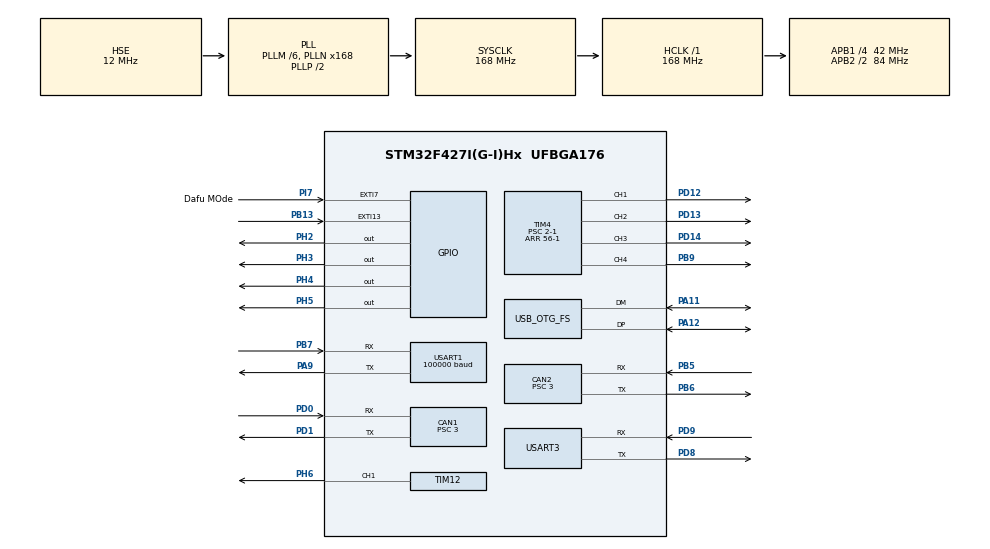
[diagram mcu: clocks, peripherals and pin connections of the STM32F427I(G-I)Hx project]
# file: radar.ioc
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CAN1.ABOM=ENABLE
CAN1.AWUM=DISABLE
CAN1.BS1=CAN_BS1_10TQ
CAN1.BS2=CAN_BS2_3TQ
CAN1.CalculateBaudRate=1000000
CAN1.CalculateTimeBit=1000
CAN1.CalculateTimeQuantum=71.42857142857143
CAN1.Prescaler=3
CAN1.TXFP=DISABLE
CAN2.ABOM=ENABLE
CAN2.AWUM=DISABLE
CAN2.BS1=CAN_BS1_10TQ
CAN2.BS2=CAN_BS2_3TQ
CAN2.CalculateBaudRate=1000000
CAN2.CalculateTimeBit=1000
CAN2.CalculateTimeQuantum=71.42857142857143
CAN2.Prescaler=3
CAN2.TXFP=DISABLE
Dma.Request0=TIM4_CH1
Dma.Request1=TIM4_CH3
Dma.Request2=TIM4_UP
Dma.Request3=USART1_RX
Dma.Request4=USART3_RX
Dma.Request5=USART3_TX
Dma.TIM4_CH1.0.Direction=DMA_MEMORY_TO_PERIPH
Dma.TIM4_CH1.0.FIFOMode=DMA_FIFOMODE_DISABLE
Dma.TIM4_CH1.0.Instance=DMA1_Stream0
Dma.TIM4_CH1.0.MemDataAlignment=DMA_MDATAALIGN_WORD
Dma.TIM4_CH1.0.MemInc=DMA_MINC_ENABLE
Dma.TIM4_CH1.0.Mode=DMA_CIRCULAR
Dma.TIM4_CH1.0.PeriphDataAlignment=DMA_PDATAALIGN_WORD
Dma.TIM4_CH1.0.PeriphInc=DMA_PINC_DISABLE
Dma.TIM4_CH1.0.Priority=DMA_PRIORITY_MEDIUM
Dma.TIM4_CH3.1.Direction=DMA_MEMORY_TO_PERIPH
Dma.TIM4_CH3.1.FIFOMode=DMA_FIFOMODE_DISABLE
Dma.TIM4_CH3.1.Instance=DMA1_Stream7
Dma.TIM4_CH3.1.MemDataAlignment=DMA_MDATAALIGN_HALFWORD
Dma.TIM4_CH3.1.MemInc=DMA_MINC_ENABLE
Dma.TIM4_CH3.1.Mode=DMA_CIRCULAR
Dma.TIM4_CH3.1.PeriphDataAlignment=DMA_PDATAALIGN_HALFWORD
Dma.TIM4_CH3.1.PeriphInc=DMA_PINC_DISABLE
Dma.TIM4_CH3.1.Priority=DMA_PRIORITY_MEDIUM
Dma.TIM4_UP.2.Direction=DMA_MEMORY_TO_PERIPH
Dma.TIM4_UP.2.FIFOMode=DMA_FIFOMODE_DISABLE
Dma.TIM4_UP.2.Instance=DMA1_Stream6
Dma.TIM4_UP.2.MemDataAlignment=DMA_MDATAALIGN_HALFWORD
Dma.TIM4_UP.2.MemInc=DMA_MINC_ENABLE
Dma.TIM4_UP.2.Mode=DMA_CIRCULAR
Dma.TIM4_UP.2.PeriphDataAlignment=DMA_PDATAALIGN_HALFWORD
Dma.TIM4_UP.2.PeriphInc=DMA_PINC_DISABLE
Dma.TIM4_UP.2.Priority=DMA_PRIORITY_MEDIUM
Dma.USART1_RX.3.Direction=DMA_PERIPH_TO_MEMORY
Dma.USART1_RX.3.FIFOMode=DMA_FIFOMODE_DISABLE
Dma.USART1_RX.3.Instance=DMA2_Stream2
Dma.USART1_RX.3.MemDataAlignment=DMA_MDATAALIGN_BYTE
Dma.USART1_RX.3.MemInc=DMA_MINC_ENABLE
Dma.USART1_RX.3.Mode=DMA_NORMAL
Dma.USART1_RX.3.PeriphDataAlignment=DMA_PDATAALIGN_BYTE
Dma.USART1_RX.3.PeriphInc=DMA_PINC_DISABLE
Dma.USART1_RX.3.Priority=DMA_PRIORITY_VERY_HIGH
Dma.USART3_RX.4.Direction=DMA_PERIPH_TO_MEMORY
Dma.USART3_RX.4.FIFOMode=DMA_FIFOMODE_DISABLE
Dma.USART3_RX.4.Instance=DMA1_Stream1
Dma.USART3_RX.4.MemDataAlignment=DMA_MDATAALIGN_BYTE
Dma.USART3_RX.4.MemInc=DMA_MINC_ENABLE
Dma.USART3_RX.4.Mode=DMA_NORMAL
Dma.USART3_RX.4.PeriphDataAlignment=DMA_PDATAALIGN_BYTE
Dma.USART3_RX.4.PeriphInc=DMA_PINC_DISABLE
Dma.USART3_RX.4.Priority=DMA_PRIORITY_LOW
Dma.USART3_TX.5.Direction=DMA_MEMORY_TO_PERIPH
Dma.USART3_TX.5.FIFOMode=DMA_FIFOMODE_DISABLE
Dma.USART3_TX.5.Instance=DMA1_Stream3
Dma.USART3_TX.5.MemDataAlignment=DMA_MDATAALIGN_BYTE
Dma.USART3_TX.5.MemInc=DMA_MINC_ENABLE
Dma.USART3_TX.5.Mode=DMA_NORMAL
Dma.USART3_TX.5.PeriphDataAlignment=DMA_PDATAALIGN_BYTE
Dma.USART3_TX.5.PeriphInc=DMA_PINC_DISABLE
Dma.USART3_TX.5.Priority=DMA_PRIORITY_LOW
Mcu.Family=STM32F4
Mcu.Name=STM32F427I(G-I)Hx
Mcu.Package=UFBGA176
NVIC.CAN1_RX0_IRQn=true\:0\:0\:false\:false\:true\:true\:true\:true
NVIC.CAN2_RX0_IRQn=true\:1\:0\:true\:false\:true\:true\:true\:true
NVIC.DMA1_Stream0_IRQn=true\:0\:0\:false\:false\:true\:false\:true\:true
NVIC.DMA1_Stream1_IRQn=true\:0\:0\:false\:false\:true\:false\:true\:true
NVIC.DMA1_Stream3_IRQn=true\:0\:0\:false\:false\:true\:false\:true\:true
NVIC.DMA1_Stream6_IRQn=true\:0\:0\:false\:false\:true\:false\:true\:true
NVIC.DMA1_Stream7_IRQn=true\:1\:0\:true\:false\:true\:false\:true\:true
NVIC.DMA2_Stream2_IRQn=true\:1\:0\:true\:false\:true\:false\:true\:true
NVIC.EXTI9_5_IRQn=true\:1\:0\:true\:false\:true\:true\:true\:true
NVIC.OTG_FS_IRQn=true\:0\:0\:false\:false\:true\:true\:true\:true
NVIC.PriorityGroup=NVIC_PRIORITYGROUP_4
NVIC.TIM8_TRG_COM_TIM14_IRQn=true\:1\:0\:true\:false\:true\:true\:true\:true
NVIC.USART1_IRQn=true\:5\:0\:true\:false\:true\:true\:true\:true
NVIC.USART3_IRQn=true\:0\:0\:false\:false\:true\:true\:true\:true
PA11.Mode=Device_Only
PA11.Signal=USB_OTG_FS_DM
PA12.Mode=Device_Only
PA12.Signal=USB_OTG_FS_DP
PA13.Mode=Serial_Wire
PA13.Signal=SYS_JTMS-SWDIO
PA14.Mode=Serial_Wire
PA14.Signal=SYS_JTCK-SWCLK
PA9.Mode=Asynchronous
PA9.Signal=USART1_TX
PB13.Signal=GPXTI13
PB5.Mode=CAN_Activate
PB5.Signal=CAN2_RX
PB6.Mode=CAN_Activate
PB6.Signal=CAN2_TX
PB7.Mode=Asynchronous
PB7.Signal=USART1_RX
PB9.Signal=S_TIM4_CH4
PC14/OSC32_IN.Mode=LSE-External-Oscillator
PC14/OSC32_IN.Signal=RCC_OSC32_IN
PC15/OSC32_OUT.Mode=LSE-External-Oscillator
PC15/OSC32_OUT.Signal=RCC_OSC32_OUT
PD0.Mode=CAN_Activate
PD0.Signal=CAN1_RX
PD1.Mode=CAN_Activate
PD1.Signal=CAN1_TX
PD12.Signal=S_TIM4_CH1
PD13.Signal=S_TIM4_CH2
PD14.Signal=S_TIM4_CH3
PD8.Mode=Asynchronous
PD8.Signal=USART3_TX
PD9.Mode=Asynchronous
PD9.Signal=USART3_RX
PH0/OSC_IN.Mode=HSE-External-Oscillator
PH0/OSC_IN.Signal=RCC_OSC_IN
PH1/OSC_OUT.Mode=HSE-External-Oscillator
PH1/OSC_OUT.Signal=RCC_OSC_OUT
PH2.GPIO_Speed=GPIO_SPEED_FREQ_VERY_HIGH
PH2.PinState=GPIO_PIN_SET
PH2.Signal=GPIO_Output
PH3.GPIO_Speed=GPIO_SPEED_FREQ_VERY_HIGH
PH3.PinState=GPIO_PIN_SET
PH3.Signal=GPIO_Output
PH4.GPIO_Speed=GPIO_SPEED_FREQ_VERY_HIGH
PH4.PinState=GPIO_PIN_SET
PH4.Signal=GPIO_Output
PH5.GPIO_Speed=GPIO_SPEED_FREQ_VERY_HIGH
PH5.PinState=GPIO_PIN_SET
PH5.Signal=GPIO_Output
PH6.Signal=S_TIM12_CH1
PI7.GPIO_Label=Dafu MOde
PI7.GPIO_ModeDefaultEXTI=GPIO_MODE_IT_FALLING
PI7.GPIO_PuPd=GPIO_PULLUP
PI7.Signal=GPXTI7
ProjectManager.HeapSize=0x200
ProjectManager.StackSize=0x400
ProjectManager.TargetToolchain=CMake
RCC.48MHZClocksFreq_Value=48000000
RCC.AHBFreq_Value=168000000
RCC.APB1CLKDivider=RCC_HCLK_DIV4
RCC.APB1Freq_Value=42000000
RCC.APB1TimFreq_Value=84000000
RCC.APB2CLKDivider=RCC_HCLK_DIV2
RCC.APB2Freq_Value=84000000
RCC.APB2TimFreq_Value=168000000
RCC.CortexFreq_Value=168000000
RCC.HCLKFreq_Value=168000000
RCC.HSE_VALUE=12000000
RCC.HSI_VALUE=16000000
RCC.PLLM=6
RCC.PLLN=168
RCC.PLLQ=7
RCC.SYSCLKFreq_VALUE=168000000
RCC.SYSCLKSource=RCC_SYSCLKSOURCE_PLLCLK
RCC.VCOOutputFreq_Value=336000000
SH.S_TIM12_CH1.0=TIM12_CH1,PWM Generation1 CH1
SH.S_TIM4_CH1.0=TIM4_CH1,PWM Generation1 CH1
SH.S_TIM4_CH2.0=TIM4_CH2,PWM Generation2 CH2
SH.S_TIM4_CH3.0=TIM4_CH3,PWM Generation3 CH3
SH.S_TIM4_CH4.0=TIM4_CH4,PWM Generation4 CH4
TIM12.AutoReloadPreload=TIM_AUTORELOAD_PRELOAD_ENABLE
TIM12.Channel-PWM\ Generation1\ CH1=TIM_CHANNEL_1
TIM12.Period=1
TIM12.Prescaler=1
TIM14.Period=2000-1
TIM14.Prescaler=90-1
TIM4.Channel-PWM\ Generation1\ CH1=TIM_CHANNEL_1
TIM4.Channel-PWM\ Generation2\ CH2=TIM_CHANNEL_2
TIM4.Channel-PWM\ Generation3\ CH3=TIM_CHANNEL_3
TIM4.Channel-PWM\ Generation4\ CH4=TIM_CHANNEL_4
TIM4.Period=56-1
TIM4.Prescaler=2-1
TIM4.Pulse-PWM\ Generation1\ CH1=15
TIM5.Period=45-1
TIM5.Prescaler=2-1
TIM8.Period=45-1
TIM8.Prescaler=2-1
USART1.BaudRate=100000
USART1.Parity=PARITY_EVEN
USART1.VirtualMode=VM_ASYNC
USART1.WordLength=WORDLENGTH_9B
USART3.VirtualMode=VM_ASYNC
USB_DEVICE.CLASS_NAME_FS=CDC
USB_DEVICE.VirtualMode-CDC_FS=Cdc
USB_DEVICE.VirtualModeFS=Cdc_FS
USB_OTG_FS.VirtualMode=Device_Only
VP_RNG_VS_RNG.Mode=RNG_Activate
VP_TIM12_VS_ClockSourceINT.Mode=Internal
VP_TIM14_VS_ClockSourceINT.Mode=Enable_Timer
VP_TIM4_VS_ClockSourceINT.Mode=Internal
VP_TIM5_VS_ClockSourceINT.Mode=Internal
VP_TIM6_VS_ClockSourceINT.Mode=Enable_Timer
VP_TIM8_VS_ClockSourceINT.Mode=Internal
VP_USB_DEVICE_VS_USB_DEVICE_CDC_FS.Mode=CDC_FS
board=custom

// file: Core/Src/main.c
/* USER CODE BEGIN Header */
/**
  ******************************************************************************
  * @file           : main.c
  * @brief          : Main program body
  ******************************************************************************
  * @attention
  *
  * Copyright (c) 2026 STMicroelectronics.
  * All rights reserved.
  *
  * This software is licensed under terms that can be found in the LICENSE file
  * in the root directory of this software component.
  * If no LICENSE file comes with this software, it is provided AS-IS.
  *
  ******************************************************************************
  */
/* USER CODE END Header */
#include "main.h"
#include "can.h"
#include "dma.h"
#include "rng.h"
#include "tim.h"
#include "usart.h"
#include "usb_device.h"
#include "gpio.h"

void SystemClock_Config(void);
/* USER CODE BEGIN PFP */
void AppMain();
/* USER CODE END PFP */

int main(void)
{

  /* MCU Configuration--------------------------------------------------------*/

  /* Reset of all peripherals, Initializes the Flash interface and the Systick. */
  HAL_Init();

  /* Configure the system clock */
  SystemClock_Config();

  /* Initialize all configured peripherals */
  MX_GPIO_Init();
  MX_DMA_Init();
  MX_TIM4_Init();
  MX_TIM6_Init();
  MX_TIM5_Init();
  MX_TIM8_Init();
  MX_CAN1_Init();
  MX_USART1_UART_Init();
  MX_CAN2_Init();
  MX_USART3_UART_Init();
  MX_TIM14_Init();
  MX_TIM12_Init();
  MX_RNG_Init();
  MX_USB_DEVICE_Init();
  /* USER CODE BEGIN 2 */
  AppMain();
  /* USER CODE END 2 */

  /* Infinite loop */
  while (1)
  {

  }
}

void SystemClock_Config(void)
{
  RCC_OscInitTypeDef RCC_OscInitStruct = {0};
  RCC_ClkInitTypeDef RCC_ClkInitStruct = {0};

  /** Configure the main internal regulator output voltage
  */
  __HAL_RCC_PWR_CLK_ENABLE();
  __HAL_PWR_VOLTAGESCALING_CONFIG(PWR_REGULATOR_VOLTAGE_SCALE1);

  /** Initializes the RCC Oscillators according to the specified parameters
  * in the RCC_OscInitTypeDef structure.
  */
  RCC_OscInitStruct.OscillatorType = RCC_OSCILLATORTYPE_HSE;
  RCC_OscInitStruct.HSEState = RCC_HSE_ON;
  RCC_OscInitStruct.PLL.PLLState = RCC_PLL_ON;
  RCC_OscInitStruct.PLL.PLLSource = RCC_PLLSOURCE_HSE;
  RCC_OscInitStruct.PLL.PLLM = 6;
  RCC_OscInitStruct.PLL.PLLN = 168;
  RCC_OscInitStruct.PLL.PLLP = RCC_PLLP_DIV2;
  RCC_OscInitStruct.PLL.PLLQ = 7;
  if (HAL_RCC_OscConfig(&RCC_OscInitStruct) != HAL_OK)
  {
    Error_Handler();
  }

  /** Initializes the CPU, AHB and APB buses clocks
  */
  RCC_ClkInitStruct.ClockType = RCC_CLOCKTYPE_HCLK|RCC_CLOCKTYPE_SYSCLK
                              |RCC_CLOCKTYPE_PCLK1|RCC_CLOCKTYPE_PCLK2;
  RCC_ClkInitStruct.SYSCLKSource = RCC_SYSCLKSOURCE_PLLCLK;
  RCC_ClkInitStruct.AHBCLKDivider = RCC_SYSCLK_DIV1;
  RCC_ClkInitStruct.APB1CLKDivider = RCC_HCLK_DIV4;
  RCC_ClkInitStruct.APB2CLKDivider = RCC_HCLK_DIV2;

  if (HAL_RCC_ClockConfig(&RCC_ClkInitStruct, FLASH_LATENCY_5) != HAL_OK)
  {
    Error_Handler();
  }
}

void Error_Handler(void)
{
  __disable_irq();
  while (1)
  {
  }
}
